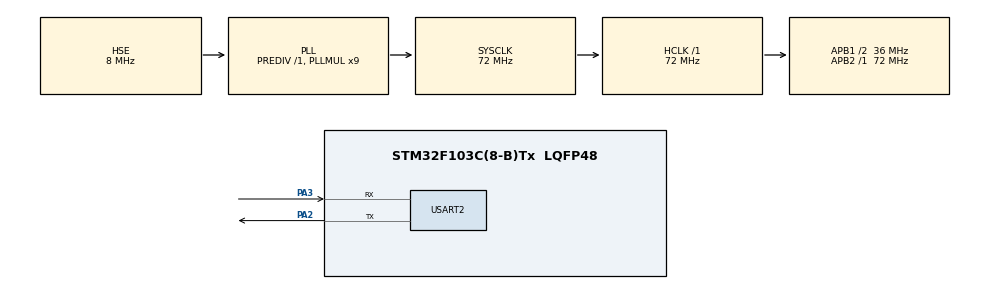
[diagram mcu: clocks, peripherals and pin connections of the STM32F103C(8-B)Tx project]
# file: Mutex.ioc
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FREERTOS.Tasks01=NormalTask1,0,128,StartNormalTask1,Default,NULL,Dynamic,NULL,NULL;NormalTask2,0,128,StartNormalTask2,Default,NULL,Dynamic,NULL,NULL;AboveNormalTask,1,128,StartAboveNormalTask,Default,NULL,Dynamic,NULL,NULL
Mcu.Family=STM32F1
Mcu.Name=STM32F103C(8-B)Tx
Mcu.Package=LQFP48
NVIC.PriorityGroup=NVIC_PRIORITYGROUP_4
NVIC.TIM4_IRQn=true\:15\:0\:false\:false\:true\:false\:false\:true\:true
NVIC.TimeBase=TIM4_IRQn
NVIC.TimeBaseIP=TIM4
PA13.Mode=Serial_Wire
PA13.Signal=SYS_JTMS-SWDIO
PA14.Mode=Serial_Wire
PA14.Signal=SYS_JTCK-SWCLK
PA2.Mode=Asynchronous
PA2.Signal=USART2_TX
PA3.Mode=Asynchronous
PA3.Signal=USART2_RX
PD0-OSC_IN.Mode=HSE-External-Oscillator
PD0-OSC_IN.Signal=RCC_OSC_IN
PD1-OSC_OUT.Mode=HSE-External-Oscillator
PD1-OSC_OUT.Signal=RCC_OSC_OUT
ProjectManager.HeapSize=0x200
ProjectManager.StackSize=0x400
ProjectManager.TargetToolchain=MDK-ARM V5.32
RCC.AHBFreq_Value=72000000
RCC.APB1CLKDivider=RCC_HCLK_DIV2
RCC.APB1Freq_Value=36000000
RCC.APB1TimFreq_Value=72000000
RCC.APB2Freq_Value=72000000
RCC.APB2TimFreq_Value=72000000
RCC.HCLKFreq_Value=72000000
RCC.PLLMUL=RCC_PLL_MUL9
RCC.PLLSourceVirtual=RCC_PLLSOURCE_HSE
RCC.SYSCLKFreq_VALUE=72000000
RCC.SYSCLKSource=RCC_SYSCLKSOURCE_PLLCLK
RCC.USBFreq_Value=72000000
USART2.VirtualMode=VM_ASYNC
VP_FREERTOS_VS_CMSIS_V1.Mode=CMSIS_V1
VP_SYS_VS_tim4.Mode=TIM4
board=custom

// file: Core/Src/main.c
/* USER CODE BEGIN Header */
/**
  ******************************************************************************
  * @file           : main.c
  * @brief          : Main program body
  ******************************************************************************
  * @attention
  *
  * Copyright (c) 2022 STMicroelectronics.
  * All rights reserved.
  *
  * This software is licensed under terms that can be found in the LICENSE file
  * in the root directory of this software component.
  * If no LICENSE file comes with this software, it is provided AS-IS.
  *
  ******************************************************************************
  */
/* USER CODE END Header */
#include "main.h"
#include "cmsis_os.h"

/* USER CODE BEGIN Includes */
#include "stdio.h"
#include "string.h"
/* USER CODE END Includes */

UART_HandleTypeDef huart2;
uint32_t NormalTaskExcutionTime_1 = 0;
uint32_t NormalTaskExcutionTime_2 = 0;
uint32_t AboveTaskExcutionTime = 0;
osThreadId NormalTask1Handle;
osThreadId NormalTask2Handle;
osThreadId AboveNormalTaskHandle;
/* USER CODE BEGIN PV */
osMutexId myMutex01Handle;
/* USER CODE END PV */

void SystemClock_Config(void);
static void MX_GPIO_Init(void);
static void MX_USART2_UART_Init(void);
void StartNormalTask1(void const * argument);
void StartNormalTask2(void const * argument);
void StartAboveNormalTask(void const * argument);

int main(void)
{

  /* MCU Configuration--------------------------------------------------------*/

  /* Reset of all peripherals, Initializes the Flash interface and the Systick. */
  HAL_Init();

  /* Configure the system clock */
  SystemClock_Config();

  /* Initialize all configured peripherals */
  MX_GPIO_Init();
  MX_USART2_UART_Init();

  /* USER CODE BEGIN RTOS_MUTEX */
  /* add mutexes, ... */
	osMutexDef(myMutex01);
	myMutex01Handle = osMutexCreate(osMutex(myMutex01));
  /* USER CODE END RTOS_MUTEX */

  /* Create the thread(s) */
  /* definition and creation of NormalTask1 */
  osThreadDef(NormalTask1, StartNormalTask1, osPriorityNormal, 0, 128);
  NormalTask1Handle = osThreadCreate(osThread(NormalTask1), NULL);

  /* definition and creation of NormalTask2 */
  osThreadDef(NormalTask2, StartNormalTask2, osPriorityNormal, 0, 128);
  NormalTask2Handle = osThreadCreate(osThread(NormalTask2), NULL);

  /* definition and creation of AboveNormalTask */
  osThreadDef(AboveNormalTask, StartAboveNormalTask, osPriorityAboveNormal, 0, 128);
  AboveNormalTaskHandle = osThreadCreate(osThread(AboveNormalTask), NULL);

  /* Start scheduler */
  osKernelStart();

  /* We should never get here as control is now taken by the scheduler */
  /* Infinite loop */
  while (1)
  {

  }
}

void SystemClock_Config(void)
{
  RCC_OscInitTypeDef RCC_OscInitStruct = {0};
  RCC_ClkInitTypeDef RCC_ClkInitStruct = {0};

  /** Initializes the RCC Oscillators according to the specified parameters
  * in the RCC_OscInitTypeDef structure.
  */
  RCC_OscInitStruct.OscillatorType = RCC_OSCILLATORTYPE_HSE;
  RCC_OscInitStruct.HSEState = RCC_HSE_ON;
  RCC_OscInitStruct.HSEPredivValue = RCC_HSE_PREDIV_DIV1;
  RCC_OscInitStruct.HSIState = RCC_HSI_ON;
  RCC_OscInitStruct.PLL.PLLState = RCC_PLL_ON;
  RCC_OscInitStruct.PLL.PLLSource = RCC_PLLSOURCE_HSE;
  RCC_OscInitStruct.PLL.PLLMUL = RCC_PLL_MUL9;
  if (HAL_RCC_OscConfig(&RCC_OscInitStruct) != HAL_OK)
  {
    Error_Handler();
  }

  /** Initializes the CPU, AHB and APB buses clocks
  */
  RCC_ClkInitStruct.ClockType = RCC_CLOCKTYPE_HCLK|RCC_CLOCKTYPE_SYSCLK
                              |RCC_CLOCKTYPE_PCLK1|RCC_CLOCKTYPE_PCLK2;
  RCC_ClkInitStruct.SYSCLKSource = RCC_SYSCLKSOURCE_PLLCLK;
  RCC_ClkInitStruct.AHBCLKDivider = RCC_SYSCLK_DIV1;
  RCC_ClkInitStruct.APB1CLKDivider = RCC_HCLK_DIV2;
  RCC_ClkInitStruct.APB2CLKDivider = RCC_HCLK_DIV1;

  if (HAL_RCC_ClockConfig(&RCC_ClkInitStruct, FLASH_LATENCY_2) != HAL_OK)
  {
    Error_Handler();
  }
}

static void MX_USART2_UART_Init(void)
{

  huart2.Instance = USART2;
  huart2.Init.BaudRate = 115200;
  huart2.Init.WordLength = UART_WORDLENGTH_8B;
  huart2.Init.StopBits = UART_STOPBITS_1;
  huart2.Init.Parity = UART_PARITY_NONE;
  huart2.Init.Mode = UART_MODE_TX_RX;
  huart2.Init.HwFlowCtl = UART_HWCONTROL_NONE;
  huart2.Init.OverSampling = UART_OVERSAMPLING_16;
  if (HAL_UART_Init(&huart2) != HAL_OK)
  {
    Error_Handler();
  }

}

static void MX_GPIO_Init(void)
{

  /* GPIO Ports Clock Enable */
  __HAL_RCC_GPIOD_CLK_ENABLE();
  __HAL_RCC_GPIOA_CLK_ENABLE();

}

void StartNormalTask1(void const * argument)
{
  /* USER CODE BEGIN 5 */
	uint8_t data[80];
	uint32_t timeStart;
	uint32_t timeEnd;
  /* Infinite loop */
  for(;;)
  {

		osMutexWait(myMutex01Handle, osWaitForever);
		timeStart = osKernelSysTick();
		sprintf((char*)data, "Normal task 1 start at %d ms\n",(int)timeStart);
		HAL_UART_Transmit(&huart2, data, strlen((char*)data),10);
		timeEnd = osKernelSysTick();
		NormalTaskExcutionTime_1 += (timeEnd-timeStart);
		sprintf((char*)data, "Normal task 1 running time %d ms\n",(int)NormalTaskExcutionTime_1);
		HAL_UART_Transmit(&huart2, data, strlen((char*)data),10);
		osMutexRelease(myMutex01Handle);
    osDelay(1000);
  }
  /* USER CODE END 5 */
}

void StartNormalTask2(void const * argument)
{
  /* USER CODE BEGIN StartNormalTask2 */
	uint8_t data[80];
	uint32_t timeStart;
	uint32_t timeEnd;
  /* Infinite loop */
  for(;;)
  {

		osMutexWait(myMutex01Handle, osWaitForever);
		timeStart = osKernelSysTick();
		sprintf((char*)data, "Normal task 2 start at %d ms\n",(int)timeStart);
		HAL_UART_Transmit(&huart2, data, strlen((char*)data),10);
		timeEnd = osKernelSysTick();
		NormalTaskExcutionTime_2 += (timeEnd-timeStart);
		sprintf((char*)data, "Normal task 2 running time %d ms\n",(int)NormalTaskExcutionTime_2);
		HAL_UART_Transmit(&huart2, data, strlen((char*)data),10);
		osMutexRelease(myMutex01Handle);
    osDelay(1000);
  }
  /* USER CODE END StartNormalTask2 */
}

void StartAboveNormalTask(void const * argument)
{
  /* USER CODE BEGIN StartAboveNormalTask */
	uint8_t data[80];
	uint32_t timeStart;
	uint32_t timeEnd;
	uint32_t count = 0;
  /* Infinite loop */
  for(;;)
  {
		timeStart = osKernelSysTick();
		osMutexWait(myMutex01Handle, osWaitForever);
		sprintf((char*)data, "Normal Task 1 excution time %d in %d minute\n",(int)NormalTaskExcutionTime_1, count);
		HAL_UART_Transmit(&huart2, data, strlen((char*)data),10);
		sprintf((char*)data, "Normal Task 2 excution time %d in %d minute\n",(int)NormalTaskExcutionTime_2, count);
		HAL_UART_Transmit(&huart2, data, strlen((char*)data),10);
		timeEnd = osKernelSysTick();
		AboveTaskExcutionTime += (timeEnd-timeStart);
		sprintf((char*)data, "Above Task excution time %d in %d minute\n",(int)AboveTaskExcutionTime, count);
		HAL_UART_Transmit(&huart2, data, strlen((char*)data),10);
		count++;
		osMutexRelease(myMutex01Handle);
		osDelay(60000);
  }
  /* USER CODE END StartAboveNormalTask */
}

void HAL_TIM_PeriodElapsedCallback(TIM_HandleTypeDef *htim)
{
  if (htim->Instance == TIM4) {
    HAL_IncTick();
  }
}

void Error_Handler(void)
{
  __disable_irq();
  while (1)
  {
  }
}
